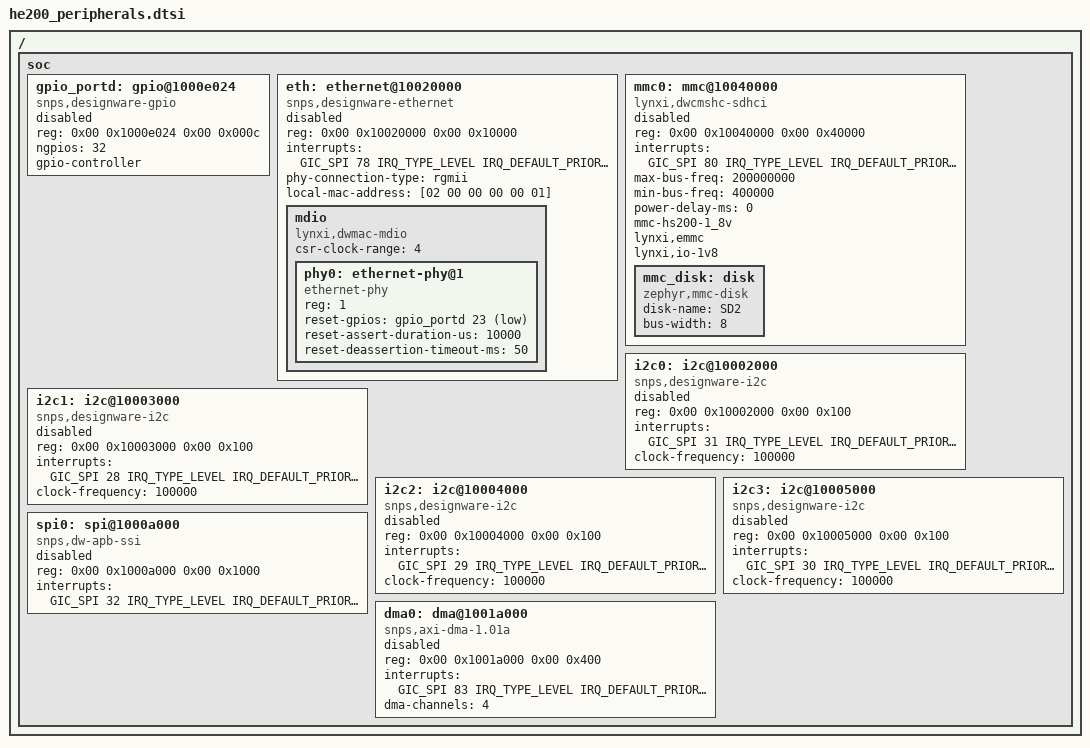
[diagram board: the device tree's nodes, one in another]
/*
 * HE200 / KA200 peripherals — aligned with lynxi-linux lynchip-lite-base.dtsi
 * and RT-Thread bsp/lynxi/he200/drivers/lynxi.h.
 *
 * All nodes default to "disabled" until Zephyr drivers + CPR clocks are ready.
 */

/ {
	soc {
		/*
		 * DesignWare GPIO block @ 0x1000e000 (Linux: snps,dw-apb-gpio).
		 * Zephyr gpio_dw: one snps,designware-gpio per port; reg low bits
		 * select port (offset 0/12/24/36 = A/B/C/D). EVB PHY reset: port D pin 23.
		 */
		gpio_portd: gpio@1000e024 {
			compatible = "snps,designware-gpio";
			reg = <0x00 0x1000e024 0x00 0x000c>;
			ngpios = <32>;
			gpio-controller;
			#gpio-cells = <2>;
			status = "disabled";
		};

		/*
		 * Linux ref: arch/arm64/boot/dts/lynxi/lynchip-lite-base.dtsi &eth
		 * EVB: lynchip-lite-evb.dts — gmac-ctrl-reg 0x1250008c, phy-mode
		 * "rgmii-id", mdio snps,dwmac-mdio, phy@1 reset-gpios portd 23.
		 * Zephyr phy-connection-type 仅支持 "rgmii"（无 rgmii-id 枚举）。
		 */
		eth: ethernet@10020000 {
			compatible = "snps,designware-ethernet";
			reg = <0x00 0x10020000 0x00 0x10000>;
			interrupts = <GIC_SPI 78 IRQ_TYPE_LEVEL IRQ_DEFAULT_PRIORITY>;
			phy-connection-type = "rgmii";
			local-mac-address = [02 00 00 00 00 01];
			status = "disabled";

			mdio: mdio {
				compatible = "lynxi,dwmac-mdio";
				#address-cells = <1>;
				#size-cells = <0>;
				csr-clock-range = <4>;

				/* PHY 型号待实板 MDIO 读 ID 后确认；先用通用 phy_mii */
				phy0: ethernet-phy@1 {
					compatible = "ethernet-phy";
					reg = <1>;
					/* lynchip-lite-evb.dts */
					reset-gpios = <&gpio_portd 23 GPIO_ACTIVE_LOW>;
					reset-assert-duration-us = <10000>;
					reset-deassertion-timeout-ms = <50>;
				};
			};
		};

		mmc0: mmc@10040000 {
			compatible = "lynxi,dwcmshc-sdhci";
			reg = <0x00 0x10040000 0x00 0x40000>;
			interrupts = <GIC_SPI 80 IRQ_TYPE_LEVEL IRQ_DEFAULT_PRIORITY>;
			max-bus-freq = <200000000>;
			min-bus-freq = <400000>;
			power-delay-ms = <0>;
			mmc-hs200-1_8v;
			lynxi,emmc;
			lynxi,io-1v8;
			status = "disabled";

			mmc_disk: disk {
				compatible = "zephyr,mmc-disk";
				disk-name = "SD2";
				bus-width = <8>;
			};
		};

		i2c0: i2c@10002000 {
			compatible = "snps,designware-i2c";
			reg = <0x00 0x10002000 0x00 0x100>;
			interrupts = <GIC_SPI 31 IRQ_TYPE_LEVEL IRQ_DEFAULT_PRIORITY>;
			clock-frequency = <100000>;
			status = "disabled";
		};

		i2c1: i2c@10003000 {
			compatible = "snps,designware-i2c";
			reg = <0x00 0x10003000 0x00 0x100>;
			interrupts = <GIC_SPI 28 IRQ_TYPE_LEVEL IRQ_DEFAULT_PRIORITY>;
			clock-frequency = <100000>;
			status = "disabled";
		};

		i2c2: i2c@10004000 {
			compatible = "snps,designware-i2c";
			reg = <0x00 0x10004000 0x00 0x100>;
			interrupts = <GIC_SPI 29 IRQ_TYPE_LEVEL IRQ_DEFAULT_PRIORITY>;
			clock-frequency = <100000>;
			status = "disabled";
		};

		i2c3: i2c@10005000 {
			compatible = "snps,designware-i2c";
			reg = <0x00 0x10005000 0x00 0x100>;
			interrupts = <GIC_SPI 30 IRQ_TYPE_LEVEL IRQ_DEFAULT_PRIORITY>;
			clock-frequency = <100000>;
			status = "disabled";
		};

		spi0: spi@1000a000 {
			compatible = "snps,dw-apb-ssi";
			reg = <0x00 0x1000a000 0x00 0x1000>;
			interrupts = <GIC_SPI 32 IRQ_TYPE_LEVEL IRQ_DEFAULT_PRIORITY>;
			#address-cells = <1>;
			#size-cells = <0>;
			status = "disabled";
		};

		dma0: dma@1001a000 {
			compatible = "snps,axi-dma-1.01a";
			reg = <0x00 0x1001a000 0x00 0x400>;
			interrupts = <GIC_SPI 83 IRQ_TYPE_LEVEL IRQ_DEFAULT_PRIORITY>;
			dma-channels = <4>;
			#dma-cells = <1>;
			status = "disabled";
		};
	};
};
